# psoc4hvpaspm10 register map
Vendor: Infineon Technologies; Series: PSOC4HVPASPM10; File version: 1.0
CPU: CM0PLUS r0p1, little endian, MPU, no FPU, VTOR, 2 interrupt priority bits, 32 interrupts
Registers are 32-bit, read-write, reset 0x0 unless marked. A register's access mark holds for its fields unless they carry their own. Offsets are from the block's base; [hi:lo] are bit positions; {n}, {i} and the like mark numbered series; 'fields as' and 'values as' point back to an identical list; <NAME> marks a mode.

## ISOUART — iso-UART Block
Base 0x402E0000
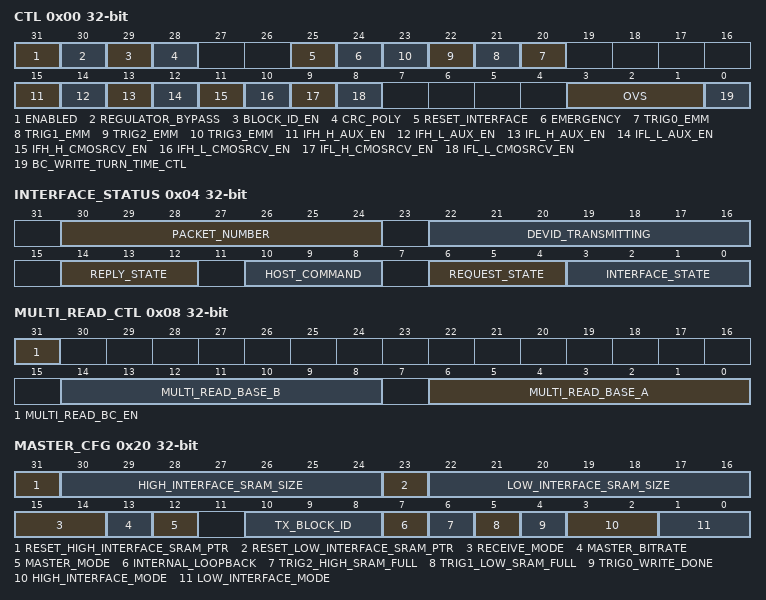
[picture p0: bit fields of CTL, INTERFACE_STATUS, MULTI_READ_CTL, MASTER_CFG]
0x00 CTL — General control register.
  [31] ENABLED — IP enabled ('1') or not ('0'). Disabling will clear all non-configuration registers.
  [30] REGULATOR_BYPASS — This bit bypasses the regulator and connects vddif directly to vddd. Regulator is bypassed in CMOS mode
    0=DISABLED (Normal mode. Wake sequence can enable the regulator); 1=ENABLED (VDDIF connected directly to VDDD for CMOS mode.)
  [29] BLOCK_ID_EN — Block ID Enable
  [28] CRC_POLY — CRC Polynomial 0: SAE J1859 : z8 + z4 + z3 + z2 + 1 1: Old CRC: x8+ x5+ x3+ x2+ x1+ x0
  [25] RESET_INTERFACE write-1-sets — Use when the interface gets stuck (i.e. when a slave fails to respond). For MASTER: resets the sequencer, clears the MASTER_START register, and prepares for another transaction. For SLAVE: moves the interface back to IDLE state
  [24] EMERGENCY write-1-sets — Declare an Emergency. Part will transmit EMM signal on the chain. Hardware will clear this bit once the full emergency signal has been sent.
  [n+20] TRIG{n}_EMM (n=0..3) — Trigger input tr_emm_in[{n}] will cause an EMM to be sent if asserted.
  [15] IFH_H_AUX_EN — Enable AUX connection from HSIOM to IFH_H allowing other peripherals to control this IO.
  [14] IFH_L_AUX_EN — Enable AUX connection from HSIOM to IFH_L allowing other peripherals to control this IO.
  [13] IFL_H_AUX_EN — Enable AUX connection from HSIOM to IFL_H allowing other peripherals to control this IO.
  [12] IFL_L_AUX_EN — Enable AUX connection from HSIOM to IFL_L allowing other peripherals to control this IO.
  [11] IFH_H_CMOSRCV_EN — Enables single ended digital receiver. Should only be enabled with AUX connection enabled.
  [10] IFH_L_CMOSRCV_EN — Enables single ended digital receiver. Should only be enabled with AUX connection enabled.
  [9] IFL_H_CMOSRCV_EN — Enables single ended digital receiver. Should only be enabled with AUX connection enabled.
  [8] IFL_L_CMOSRCV_EN — Enables single ended digital receiver. Should only be enabled with AUX connection enabled.
  [3:1] OVS
  [0] BC_WRITE_TURN_TIME_CTL — Broadcast Write Turnaround time control. 0 = normal turnaround time. Must be set to 0 when clk_sys > clk_iuart. 1 = fast turnaround time. Must be set to 1 when clk_sys <= clk_iuart. NOTE: This bitfield is only relevant in peripheral role and if IF_CONFIG.FN = 0.
0x04 INTERFACE_STATUS ro — Current state of the interface
  [30:24] PACKET_NUMBER — The packet number being transmitted. Valid when HOST_COMMAND = MULTI_READ or BC_MULTI_READ. A packet is defined as the five frames ID, Addr, Data1, Data0, and CRC. 0 = first packet
  [22:16] DEVID_TRANSMITTING — Device ID of the device currently transmitting. Valid in any state other than SLEEP, INIT, IDLE, and EMM. DEVID=0 for host, actual Device ID for any slave.
  [14:12] REPLY_STATE — Sub-state from any state where a reply is being sent by any slave. Valid for an INTERFACE_STATE where a slave is transmitting: REVERSE, REPLY, BC_WAIT, BC_REPLY, and BC_REVERSE.
    0=REPLY_FRAME (A Reply frame is being sent); 1=ID_FRAME (An ID frame is being sent); 2=ADDR_FRAME (An Address frame is being sent); 3=DATA1_FRAME (A Data1 frame is being sent); 4=DATA0_FRAME (A Data0 frame is being sent); 5=CRC_FRAME (A CRC frame is being sent)
  [10:8] HOST_COMMAND — Command type sent by host. Valid for an INTERFACE_STATE where a slave is transmitting: REVERSE, REPLY, BC_WAIT, BC_REPLY, BC_REVERSE.
    0=WRITE (Host issued a Write command); 1=BC_WRITE (Host issued a Broadcast Write command); 2=READ (Host issued a Read command); 3=MULTI_READ (Host issued a Multi-Read command); 4=BC_READ (Host issued a Broadcast Read command); 5=BC_MULTI_READ (Host issued a Broadcast Multi-Read command)
  [6:4] REQUEST_STATE — Sub-state from REQUEST state. This register is not valid if INTERFACE_STATE != REQUEST.
    0=BLOCK_ID (Host is sending SYNC-Frame); 1=DEVICE_ID (Host is sending ID-Frame); 2=ADDR (Host is sending ADDR-Frame); 3=DATA1 (Host is sending DATA1-Frame); 4=DATA0 (Host is sending DATA0-Frame); 5=CRC (Host is sending CRC-Frame)
  [3:0] INTERFACE_STATE — This register shows the current state of the interface logic
    0=SLEEP (Interface is in SLEEP state); 1=INIT (Interface is in INIT state, wakeup has been received); 2=IDLE (Interface is in IDLE state); 3=REQUEST (Interface is in REQUEST state, start bit of Sync-Frame to end of CRC Frame); 4=REVERSE (Interface is in REVERSE state, upstream device is transmitting. If MASTER then Node is responding with WRITE REPLY, READ REPLY or MULTIREAD REPLY); 5=REPLY (Interface is in REPLY state, we are transmitting); 6=BC_WAIT (Interface is in BC_WAIT state, downstream device is transmitting. If MASTER then Node is responding to broadcast read or broadcast multiread); 7=BC_REPLY (Interface is in BC_REPLY state, we are transmitting); 8=BC_REVERSE (Interface is in BC_REVERSE state, upstream device is transmitting); 9=EMM (Interface is in EMM state, EMM was detected from INIT state and we are transmitting)
0x08 MULTI_READ_CTL — Control interpretation of the multi-read configuration register
  [31] MULTI_READ_BC_EN — Enables Multi Read Broadcast
  [14:8] MULTI_READ_BASE_B — Base addresses used when returning registers enabled by bits 8 and 7:5 of the multi-read configuration register.
  [6:0] MULTI_READ_BASE_A — Base addresses used when returning registers enabled by bits 4 and 3:0 of the multi-read configuration register.
0x20 MASTER_CFG — Master configuration register
  [31] RESET_HIGH_INTERFACE_SRAM_PTR write-1-sets — Writing a 1 causes the next read to start at the beginning of the allocated SRAM space. This bit is cleared by hardware after the internal pointer is reset.
  [30:24] HIGH_INTERFACE_SRAM_SIZE — See LOW_INTERFACE_SRAM_SIZE for full description. HIGH SRAM allocation starts immediately after the LOW allocation in Loop configuration. In a non-ring configuration, SRAM pointer always starts at 0. In MoT, LOW_INTERFACE_SRAM_SIZE is used and HIGH_INTERFACE_SRAM_SIZE is ignored and in MoB HIGH_INTERFACE_SRAM_SIZE is used and LOW_INTERFACE_SRAM_SIZE is ignored. This is because if the configuration is non-ring then the node response will only come in one direction so no SRAM is assigned to the opposite direction, and the pointer always starts from 0
  [23] RESET_LOW_INTERFACE_SRAM_PTR write-1-sets — Writing a 1 causes the next read to start at the beginning of the allocated SRAM space. This bit is cleared by hardware after the internal pointer is reset.
  [22:16] LOW_INTERFACE_SRAM_SIZE
  [15:14] RECEIVE_MODE — Specifies what is done with the data that is received.
    0=REGISTER (Stored in respective RECEIVED register only); 1=UNPACKED (Unpacked, with Data field being stored in local SRAM); 2=RAW (Raw register values stored in local SRAM. This allows for end (slave) to end (ASIL-D host) data integrity to be maintained.); 3=RSVD (N/A)
  [13] MASTER_BITRATE — Determines the datarate of the ISOUART chain
    0=2_1Mbps (Set datarate to 2.1Mbps); 1=3_0Mbps (Set datarate to 3.0Mbps)
  [12] MASTER_MODE
    0=MANUAL (Send and receive data one byte at a time. No interface interpretation of the contents); 1=SEQUENCED (Perform Write and Read Transactions with a single register write)
  [10:8] TX_BLOCK_ID — Determines the blockID to be sent. Legal values are 0 - 6.
  [7] INTERNAL_LOOPBACK — Local loopback control. Value is ignored unless one interface is configured as MASTER and other as RECEIVER.
  [6] TRIG2_HIGH_SRAM_FULL — Specifies whether output trigger 2 asserts when data is written into the last allocated address in local SRAM
    0=NO_TRIGGER (No trigger, interrupt only); 1=TRIGGER (Both interrupt and trigger output are asserted)
  [5] TRIG1_LOW_SRAM_FULL — Specifies whether output trigger 1 asserts when data is written into the last allocated address in local SRAM
    values as TRIG2_HIGH_SRAM_FULL
  [4] TRIG0_WRITE_DONE — Specifies whether output trigger 0 asserts when a transaction (either manual write, or sequence) is complete
    values as TRIG2_HIGH_SRAM_FULL
  [3:2] HIGH_INTERFACE_MODE — Allows software to read the current contents of the MUILTI_READ_CFG register. Cannot be written by software since this register must be identical in all parts in the chain.
    0=SLAVE (Interface is a slave in the chain. Both interfaces must be configured as slave for proper operation.); 1=RECEIVER (Interface is the end point for loop topology); 2=MASTER (Interface is the master of a chain); 3=RSVD (N/A)
  [1:0] LOW_INTERFACE_MODE — Determines the operating mode for the LOW interface
    0=SLAVE (Interface is a slave in the chain. Both interfaces must be configured as slave for proper operation.); 1=RECEIVER (Interface is the end point for loop topology, or waiting for reply from slave); 2=MASTER (Interface is the master of a chain); 3=RSVD (N/A)
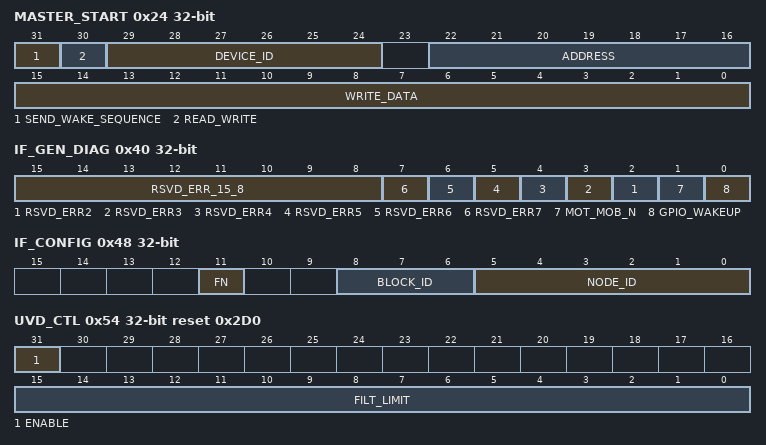
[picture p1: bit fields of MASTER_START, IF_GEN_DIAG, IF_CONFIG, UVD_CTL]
0x24 MASTER_START — Trigger a write to the interface
  [31] SEND_WAKE_SEQUENCE write-1-sets — Send wake sequence before command frame
  [30] READ_WRITE write-1-sets — When MASTER_MODE is SEQUENCED: Determines the type of sequence to be initiated
    0=READ (Read operation to transfer data from referenced slave(s)); 1=WRITE (Write operation to transfer data to referenced slave(s))
  [29:24] DEVICE_ID write-1-sets — When MASTER_MODE is SEQUENCED: Represents the slave ID(s) to be targeted with the sequence
  [22:16] ADDRESS write-1-sets — When MASTER_MODE is SEQUENCED: Represents the address of the slave(s) to be targeted with the sequence
  [15:0] WRITE_DATA write-1-sets — When MASTER_MODE is MANUAL: DATA<7:0> represents exact data to be sent onto the bus When MASTER_MODE is SEQUENCED and R_W field is Write: Data<15:0> represents the 16 bit data being sent to the specified slave(s) In all other cases, this field is ignored
0x28 LOW_INTERFACE_READ ro — Most recent data read from LOW interface
  [7:0] READ_LOW_DATA — Raw DATA received in most recent frame
0x2C HIGH_INTERFACE_READ ro — Most recent data read from HIGH interface
  [7:0] READ_HIGH_DATA — Raw DATA received in most recent frame
0x30 WAKE_DELAY_CFG reset 0x2EE0 — Wake sequence configuration
  [13:0] WAKE_CMD_DELAY — Delay between wake sequence and command frame. Default is 500us (max twake of TLE9012). Each addition adds 0.0416us of delay
0x40 IF_GEN_DIAG — General Diagnosis
  [15:8] RSVD_ERR_15_8
  [n] RSVD_ERR{n} (n=2..7)
  [1] MOT_MOB_N ro — Master on Top/Bottom Configuraiton 0 - configured as master on bottom 1 - configured as master on top
  [0] GPIO_WAKEUP ro — Wake-up via GPIO 0 - wake-up via iso UART 1 - wake-up via GPIO
0x44 IF_MULTI_READ_CFG ro — Multi-read configuration register
  [15:0] MULTI_READ_CFG — Allows software to read the current contents of the MUILTI_READ_CFG register. Cannot be written by software since this register must be identical in all parts in the chain.
0x48 IF_CONFIG ro — Interface configuration register, containing the current Device ID
  [11] FN — The final node in the stack must have this bit set. If the final node does not have FN set, no reply frame on broadcast will be sent -> UART time out 0 - not the final node (default) 1 - final node
  [8:6] BLOCK_ID — Block ID assigned to the node. Extracted from Sync frame. Only useful when blockid feature is enabled
  [5:0] NODE_ID
0x4C IF_WDOG_CNT reset 0x7F — Interface watchdog register
  [15:0] WDOG_CNT — Watchdog Count Value. Configurable by SW and shows status of count value.
0x50 CLK_STATUS ro reset not defined — Interface clock status
  [7:0] BR_COUNTER — Amount of peripheral clock periods that constitute the transmission of the sync frame as determined by the receiver. BR_COUNTER / 8 is the amount of peripheral clock periods that constitute a bit period. Used by the interface to automatically adjust the baud rate to track the host.
0x54 UVD_CTL reset 0x2D0 — Under Voltage Detection Control
  [31] ENABLE — Enable Under Voltage Detection (UVD)
  [15:0] FILT_LIMIT — Selects the glitch filter counter value limit for the UVD. If the glitch filter counter = FILT_LIMIT, the UVD interrupt will be asserted.Max value for this filter is 0x4B0, and default value is 0x2D0. Each addition adds 0.0208us of filter time
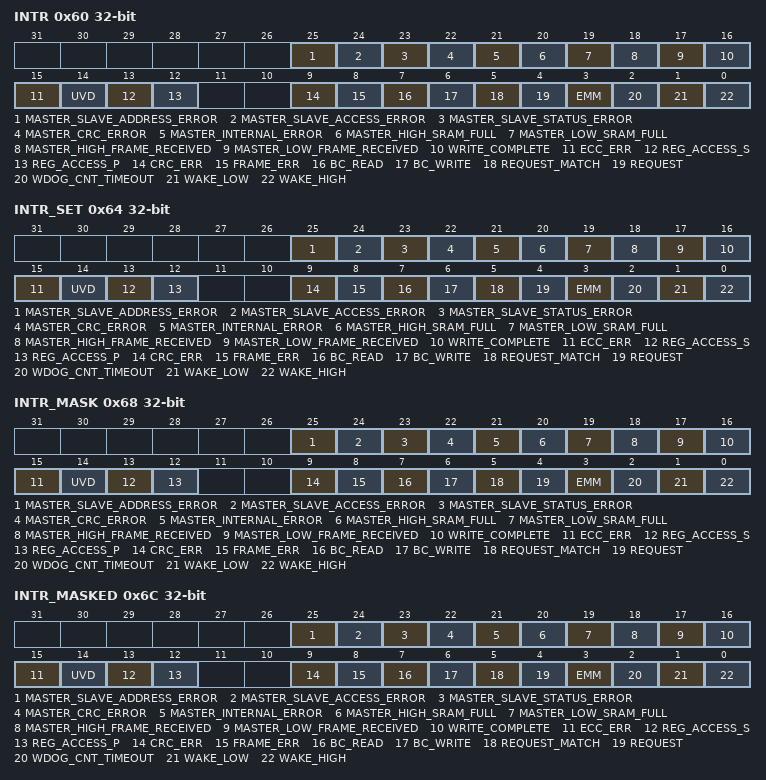
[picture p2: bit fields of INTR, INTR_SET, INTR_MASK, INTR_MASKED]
0x60 INTR — Interrupt request register
  [25] MASTER_SLAVE_ADDRESS_ERROR write-1-clears — The slave returned a reply frame with address error bit set
  [24] MASTER_SLAVE_ACCESS_ERROR write-1-clears — The slave returned a reply frame with access error bit set
  [23] MASTER_SLAVE_STATUS_ERROR write-1-clears — The slave returned a reply frame with status error bit set
  [22] MASTER_CRC_ERROR write-1-clears — A CRC value from slave didn't match expected value
  [21] MASTER_INTERNAL_ERROR write-1-clears — An internal error (i.e. configuration problem) occurred
  [20] MASTER_HIGH_SRAM_FULL write-1-clears — The HIGH interface filled the allocated local SRAM
  [19] MASTER_LOW_SRAM_FULL write-1-clears — The LOW interface filled the allocated local SRAM
  [18] MASTER_HIGH_FRAME_RECEIVED write-1-clears — A frame was received at the HIGH interface while not in SLAVE mode
  [17] MASTER_LOW_FRAME_RECEIVED write-1-clears — A frame was received at the LOW interface while not in SLAVE mode
  [16] WRITE_COMPLETE write-1-clears — A master transaction completed
  [15] ECC_ERR write-1-clears — ECC Error
  [14] UVD write-1-clears — Under Voltage Detection
  [13] REG_ACCESS_S write-1-clears — Secondary register specific access interrupt
  [12] REG_ACCESS_P write-1-clears — Primary register specific access interrupt
  [9] CRC_ERR write-1-clears — CRC error
  [8] FRAME_ERR write-1-clears — Framing communication error
  [7] BC_READ write-1-clears — The host completed a BC_READ request
  [6] BC_WRITE write-1-clears — The host completed a BC_WRITE request
  [5] REQUEST_MATCH write-1-clears — The host completed a request, with device ID matching ours, with clean CRC
  [4] REQUEST write-1-clears — The host completed a request, with clean CRC (whether or not it was addressed to us)
  [3] EMM write-1-clears — The Emergency signal was transmitted by another part in the chain
  [2] WDOG_CNT_TIMEOUT write-1-clears — Timeout of the watchdog counter, indicating that the interface is going to sleep mode
  [1] WAKE_LOW write-1-clears — Wakeup Event on Low Interface
  [0] WAKE_HIGH write-1-clears — Wakeup Event on High Interface
0x64 INTR_SET — Interrupt set register
  [25] MASTER_SLAVE_ADDRESS_ERROR write-1-sets — Write with '1' to set corresponding bit in interrupt request register.
  [24] MASTER_SLAVE_ACCESS_ERROR write-1-sets — Write with '1' to set corresponding bit in interrupt request register.
  [23] MASTER_SLAVE_STATUS_ERROR write-1-sets — Write with '1' to set corresponding bit in interrupt request register.
  [22] MASTER_CRC_ERROR write-1-sets — Write with '1' to set corresponding bit in interrupt request register.
  [21] MASTER_INTERNAL_ERROR write-1-sets — Write with '1' to set corresponding bit in interrupt request register.
  [20] MASTER_HIGH_SRAM_FULL write-1-sets — Write with '1' to set corresponding bit in interrupt request register.
  [19] MASTER_LOW_SRAM_FULL write-1-sets — Write with '1' to set corresponding bit in interrupt request register.
  [18] MASTER_HIGH_FRAME_RECEIVED write-1-sets — Write with '1' to set corresponding bit in interrupt request register.
  [17] MASTER_LOW_FRAME_RECEIVED write-1-sets — Write with '1' to set corresponding bit in interrupt request register.
  [16] WRITE_COMPLETE write-1-sets — Write with '1' to set corresponding bit in interrupt request register.
  [15] ECC_ERR write-1-sets — Write with '1' to set corresponding bit in interrupt request register.
  [14] UVD write-1-sets — Write with '1' to set corresponding bit in interrupt request register.
  [13] REG_ACCESS_S write-1-sets — Write with '1' to set corresponding bit in interrupt request register.
  [12] REG_ACCESS_P write-1-sets — Write with '1' to set corresponding bit in interrupt request register.
  [9] CRC_ERR write-1-sets — Write with '1' to set corresponding bit in interrupt request register.
  [8] FRAME_ERR write-1-sets — Write with '1' to set corresponding bit in interrupt request register.
  [7] BC_READ write-1-sets — Write with '1' to set corresponding bit in interrupt request register.
  [6] BC_WRITE write-1-sets — Write with '1' to set corresponding bit in interrupt request register.
  [5] REQUEST_MATCH write-1-sets — Write with '1' to set corresponding bit in interrupt request register.
  [4] REQUEST write-1-sets — Write with '1' to set corresponding bit in interrupt request register.
  [3] EMM write-1-sets — Write with '1' to set corresponding bit in interrupt request register.
  [2] WDOG_CNT_TIMEOUT write-1-sets — Write with '1' to set corresponding bit in interrupt request register.
  [1] WAKE_LOW write-1-sets — Write with '1' to set corresponding bit in interrupt request register.
  [0] WAKE_HIGH write-1-sets — Write with '1' to set corresponding bit in interrupt request register.
0x68 INTR_MASK — Interrupt mask register
  [25] MASTER_SLAVE_ADDRESS_ERROR — Mask bit for corresponding bit in interrupt request register.
  [24] MASTER_SLAVE_ACCESS_ERROR — Mask bit for corresponding bit in interrupt request register.
  [23] MASTER_SLAVE_STATUS_ERROR — Mask bit for corresponding bit in interrupt request register.
  [22] MASTER_CRC_ERROR — Mask bit for corresponding bit in interrupt request register.
  [21] MASTER_INTERNAL_ERROR — Mask bit for corresponding bit in interrupt request register.
  [20] MASTER_HIGH_SRAM_FULL — Mask bit for corresponding bit in interrupt request register.
  [19] MASTER_LOW_SRAM_FULL — Mask bit for corresponding bit in interrupt request register.
  [18] MASTER_HIGH_FRAME_RECEIVED — Mask bit for corresponding bit in interrupt request register.
  [17] MASTER_LOW_FRAME_RECEIVED — Mask bit for corresponding bit in interrupt request register.
  [16] WRITE_COMPLETE — Mask bit for corresponding bit in interrupt request register.
  [15] ECC_ERR — Mask bit for corresponding bit in interrupt request register.
  [14] UVD — Mask bit for corresponding bit in interrupt request register.
  [13] REG_ACCESS_S — Mask bit for corresponding bit in interrupt request register.
  [12] REG_ACCESS_P — Mask bit for corresponding bit in interrupt request register.
  [9] CRC_ERR — Mask bit for corresponding bit in interrupt request register.
  [8] FRAME_ERR — Mask bit for corresponding bit in interrupt request register.
  [7] BC_READ — Mask bit for corresponding bit in interrupt request register.
  [6] BC_WRITE — Mask bit for corresponding bit in interrupt request register.
  [5] REQUEST_MATCH — Mask bit for corresponding bit in interrupt request register.
  [4] REQUEST — Mask bit for corresponding bit in interrupt request register.
  [3] EMM — Mask bit for corresponding bit in interrupt request register.
  [2] WDOG_CNT_TIMEOUT — Mask bit for corresponding bit in interrupt request register.
  [1] WAKE_LOW — Mask bit for corresponding bit in interrupt request register.
  [0] WAKE_HIGH — Mask bit for corresponding bit in interrupt request register.
0x6C INTR_MASKED ro — Interrupt masked register
  [25] MASTER_SLAVE_ADDRESS_ERROR — Logical and of corresponding request and mask bits.
  [24] MASTER_SLAVE_ACCESS_ERROR — Logical and of corresponding request and mask bits.
  [23] MASTER_SLAVE_STATUS_ERROR — Logical and of corresponding request and mask bits.
  [22] MASTER_CRC_ERROR — Logical and of corresponding request and mask bits.
  [21] MASTER_INTERNAL_ERROR — Logical and of corresponding request and mask bits.
  [20] MASTER_HIGH_SRAM_FULL — Logical and of corresponding request and mask bits.
  [19] MASTER_LOW_SRAM_FULL — Logical and of corresponding request and mask bits.
  [18] MASTER_HIGH_FRAME_RECEIVED — Logical and of corresponding request and mask bits.
  [17] MASTER_LOW_FRAME_RECEIVED — Logical and of corresponding request and mask bits.
  [16] WRITE_COMPLETE — Logical and of corresponding request and mask bits.
  [15] ECC_ERR — Logical and of corresponding request and mask bits.
  [14] UVD — Logical and of corresponding request and mask bits.
  [13] REG_ACCESS_S — Logical and of corresponding request and mask bits.
  [12] REG_ACCESS_P — Logical and of corresponding request and mask bits.
  [9] CRC_ERR — Logical and of corresponding request and mask bits.
  [8] FRAME_ERR — Logical and of corresponding request and mask bits.
  [7] BC_READ — Logical and of corresponding request and mask bits.
  [6] BC_WRITE — Logical and of corresponding request and mask bits.
  [5] REQUEST_MATCH — Logical and of corresponding request and mask bits.
  [4] REQUEST — Logical and of corresponding request and mask bits.
  [3] EMM — Logical and of corresponding request and mask bits.
  [2] WDOG_CNT_TIMEOUT — Logical and of corresponding request and mask bits.
  [1] WAKE_LOW — Logical and of corresponding request and mask bits.
  [0] WAKE_HIGH — Logical and of corresponding request and mask bits.
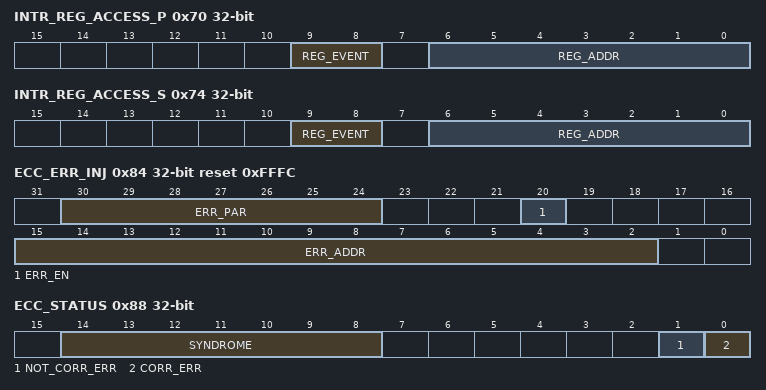
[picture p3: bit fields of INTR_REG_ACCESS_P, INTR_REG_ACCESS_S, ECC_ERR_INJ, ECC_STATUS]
0x70 INTR_REG_ACCESS_P ro — Primary Register specific access interrupt cause
  [9:8] REG_EVENT — The event that triggered the interrupt
    1=WRITE (A write event occurred); 2=EARLY_READ (An early read event occurred); 3=LATE_READ (A late read event occurred)
  [6:0] REG_ADDR — Address of request that triggered the interrupt
0x74 INTR_REG_ACCESS_S ro — Secondary Register specific access interrupt cause
  fields as INTR_REG_ACCESS_P
0x80 ECC_CTL — ECC control
  [16] ECC_EN — Enable ECC for ISOUART SRAM When disabled also all error injection functionality is disabled.
0x84 ECC_ERR_INJ reset 0xFFFC — ECC error injection
  [30:24] ERR_PAR — ECC Parity bits to use for ECC error injection at address ERR_ADDR.
  [20] ERR_EN — Enable error injection (ECC_EN must be 1). When this bit is set the error parity (ERR_PAR) will be used when an AHB write is done to the ERR_ADDR address. When the error word is read a single or double error will be reported to the fault structure just like for a real ECC error (even if this bit is no longer set). When this bit is set (and ECC_EN=1) a non-correctable error (ECC or address error) for the ERR_ADDR will not be reported back to the ISOUART or AHB bus.
  [15:2] ERR_ADDR — Specifies the address of the word where an error will be injected on write or an non-correctable error will be suppressed. When the ERR_EN bit is set an error parity (ERR_PAR) is injected when any write is done to this address. When the ERR_EN bit is set and the access address matches ERR_ADDR then a non-correctable ECC error or an Address error will NOT result in a bus error or ISOUART shutdown. This address must be the AHB address (i.e. SRAM_WITH_ATTR) Note that error reporting to the fault structure cannot be suppressed.
0x88 ECC_STATUS ro
  [14:8] SYNDROME — ECC Error Syndrome, can be used to determine the bit location on correctable ECC Errors
  [1] NOT_CORR_ERR — Not Corrected ECC Error
  [0] CORR_ERR — Corrected ECC Error
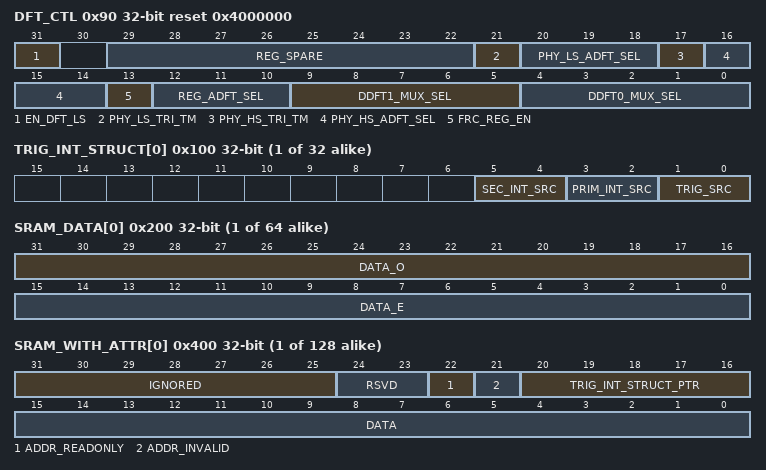
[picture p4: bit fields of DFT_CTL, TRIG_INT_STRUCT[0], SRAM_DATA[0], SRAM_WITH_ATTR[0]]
0x90 DFT_CTL reset 0x4000000 — DFT Control Register
  [31] EN_DFT_LS — Enable DFT Stuck-At-1 Test for Level Shifters
  [29:22] REG_SPARE — Regulator Spares Controls
  [21] PHY_LS_TRI_TM — Low Side Physically Interface Tri-state Test Mode 0 - Functional Mode 1 - Tri-state LS PHY Interface
  [20:18] PHY_LS_ADFT_SEL — Low Side Physical Interface ADFT select below selections correspond to amuxbusa, amuxbusb 0 - Hi-Z, Hi-Z 1 - sense_h_rec, sense_l_rec 2 - sense_h_wake, sense_l_wake 3 - sense_h_cmosi, sense_l_cmosi 4 - rec_ith_offset, Hi-Z 5 - wake_lch_h, wake_lch_l 6 - wake_g, wake_rstn 7 - wake_g, wake_output
  [17] PHY_HS_TRI_TM — High Side Physically Interface Tri-state Test Mode 0 - Functional Mode 1 - Tri-state HS PHY Interface
  [16:14] PHY_HS_ADFT_SEL — High Side Physical Interface ADFT select below selections correspond to amuxbusa, amuxbus 0 - Hi-Z, Hi-Z 1 - sense_h_rec, sense_l_rec 2 - sense_h_wake, sense_l_wake 3 - sense_h_cmosi, sense_l_cmosi 4 - rec_ith_offset, Hi-Z 5 - wake_lch_h, wake_lch_l 6 - wake_g, wake_rstn 7 - wake_g, wake_output
  [13] FRC_REG_EN — Force Regulator Enable CTL.REGULATOR_ENABLE enables the regulator but requires a wake sequencer before the regulator is actually enabled. FRC_REG_EN enables the regulator without a wake sequence. This bit is used for testing and should be set to 0 in functional mode. 0 - Functional mode 1 - Force Regulator enable for testing
  [12:10] REG_ADFT_SEL — Regulator ADFT Select below selections correspond to amuxbusa,amuxbusb 0 - Hi-Z, Hi-Z: Disabled 1 - uv_n, Hi-Z: Undervoltage comparator test 2 - vddif, vddif_s: Internal vdddif measure 3 - internal regulator bias current output, internal comparator bias current output: Internal bias current measure 4 - internal comparator bias current output , internal regulator bias current output,: Internal bias current measure (swapped) 5 - Hi-Z, Hi-Z: Discharge off mode 6 - Hi-Z, Hi-Z: Current limit disable mode 7 - Hi-Z, Hi-Z: Burn-In mode
  [9:5] DDFT1_MUX_SEL — DDFT1 Output Mux Selection 0 - off (low) 1 - wake_hs 2 - wake_ls 3 - reg_en 4 - hs_pd_rec (High PHY powerdown receiver) 5 - hs_en_tr (High PHY enable transmitter) 6 - ls_pd_rec (Low PHY powerdown receiver) 7 - ls_en_tr (Low PHY enable transmitter) 8 - hs_if_mode 9 - ls_if_mode 10 - hs_trn_tri 11 - ls_trn_tri 12 - hs_datain 13 - ls_datain 14 - wake_reset (input to PHY. From logic prespective there is onlay a single wake reset which goes to both PHY) 15 - reg_uv_n (output from regulator) 16 - reg_vddif_sel (input to regulator) 17 - hs_data_out 18 - ls_data_out
  [4:0] DDFT0_MUX_SEL — DDFT0 Output Mux Selection 0 - off (low) 1 - wake_hs (output from PHY) 2 - wake_ls (output from PHY) 3 - reg_en (input to regulator) 4 - hs_pd_rec (High PHY powerdown receiver) (input to PHY) 5 - hs_en_tr (High PHY enable transmitter) (input to PHY) 6 - ls_pd_rec (Low PHY powerdown receiver) (input to PHY) 7 - ls_en_tr (Low PHY enable transmitter) (input to PHY) 8 - hs_if_mode (input to PHY) 9 - ls_if_mode (input to PHY) 10 - hs_trn_tri (input to PHY) 11 - ls_trn_tri (input to PHY) 12 - hs_datain (output from PHY) 13 - ls_datain (output to PHY) 14 - wake_reset (input to PHY. From logic prespective there is onlay a single wake reset which goes to both PHY) 15 - reg_uv_n 16 - reg_vddif_sel (input to regulator) 17 - hs_data_out 18 - ls_data_out
0x94 DFT_STATUS ro
  [0] DFT_LS_OUT — Observation point of level-shifters output. Used for detection of SA1 faults on the level-shifter enables.
{0x100+4i} TRIG_INT_STRUCT[{i}] (i=0..31) — Structure defining trigger and interrupt response to events
  [5:4] SEC_INT_SRC — Determines whether the secondary interrupt is enabled, and when it is asserted
    0=NONE (No Interrupt); 1=WRITE (Interrupt on a write event); 2=EARLY_READ (Interrupt on an early read event); 3=LATE_READ (Interrupt on a late read event)
  [3:2] PRIM_INT_SRC — Determines whether the primary interrupt is enabled, and when it is asserted
    values as SEC_INT_SRC
  [1:0] TRIG_SRC — Determines whether a trigger is enabled, and when it is asserted
    0=NONE (No trigger); 1=WRITE (Trigger on a write event); 2=EARLY_READ (Trigger on an early read event); 3=LATE_READ (Trigger on a late read event)
{0x200+4i} SRAM_DATA[{i}] (i=0..63) reset not defined — 128 word x 16 bit SRAM representing data available to iso-UART interface
  [31:16] DATA_O — 16 bit data field (odd row). Same content as SRAM_WITH_ATTR.DATA Writes to this address space only affect the data portion of SRAM, and reads only return the DATA portion of the SRAM. Since the data filed of each SRAM row is only 16 bit wide, read/writes to this offset accesses 2 consecutive SRAM locations to provide 32 bits.
  [15:0] DATA_E — 16 bit data field (even row). Same content as SRAM_WITH_ATTR.DATA Writes to this address space only affect the data portion of SRAM, and reads only return the DATA portion of the SRAM. Since the data filed of each SRAM row is only 16 bit wide, read/writes to this offset accesses 2 consecutive SRAM locations to provide 32 bits.
{0x400+4i} SRAM_WITH_ATTR[{i}] (i=0..127) reset not defined — 128 word x 16 bit (only 9 usable bits) containing attributes
  [31:25] IGNORED ro — ECC parity is stored in these bits of the SRAM. ECC parity is set and read in hardware and are not directly accessible. Writes to these bits are ignored. Reads always return zero for these bits. To test ECC functionality, use the ECC_ERR_INJ register
  [24:23] RSVD
  [22] ADDR_READONLY — This address is read-only. If high, write access by iso-UART generates read only register error
  [21] ADDR_INVALID — This address is valid. If high, access by iso-UART generates invalid address error
  [20:16] TRIG_INT_STRUCT_PTR — Pointer to the Trig_Int_Struct entry for this address
  [15:0] DATA — 16 bit data field. Same content as SRAM_DATA.DATA
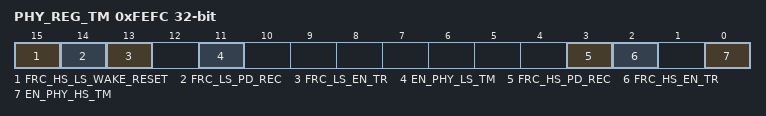
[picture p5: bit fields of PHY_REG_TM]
0xFEFC PHY_REG_TM — Test Mode Register
  [15] FRC_HS_LS_WAKE_RESET — Force PHY HS & LS WAKE_RESET
  [14] FRC_LS_PD_REC — Force PHY LS PD_REC
  [13] FRC_LS_EN_TR — Force PHY LS EN_TR
  [11] EN_PHY_LS_TM — Enable PHY LS Test Mode
  [3] FRC_HS_PD_REC — Force PHY HS PD_REC
  [2] FRC_HS_EN_TR — Force PHY HS EN_TR
  [0] EN_PHY_HS_TM — Enable PHY HS Test Mode
0xFF00 TRIM_PHY_V_HS — Internal Voltage Trim for HS PHY
  [7:0] INT_VOLT — Internal Voltage Trim
0xFF04 TRIM_PHY_V_LS — Internal Voltage Trim for LS PHY
  [7:0] INT_VOLT — Internal Voltage Trim
0xFF08 TRIM_PHY_ITH_HS — Current Trim for HS PHY
  [2:0] CURR — Current Trim
0xFF0C TRIM_PHY_ITH_LS — Current Trim for LS PHY
  [2:0] CURR — Current Trim
